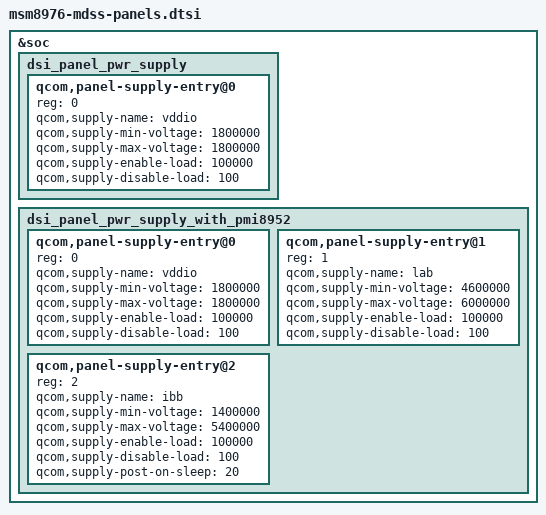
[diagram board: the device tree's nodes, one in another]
/* Copyright (c) 2015, The Linux Foundation. All rights reserved.
 *
 * This program is free software; you can redistribute it and/or modify
 * it under the terms of the GNU General Public License version 2 and
 * only version 2 as published by the Free Software Foundation.
 *
 * This program is distributed in the hope that it will be useful,
 * but WITHOUT ANY WARRANTY; without even the implied warranty of
 * MERCHANTABILITY or FITNESS FOR A PARTICULAR PURPOSE.  See the
 * GNU General Public License for more details.
 */

#include "dsi-panel-sim-video.dtsi"
#include "dsi-panel-sim-cmd.dtsi"
#include "dsi-panel-nt35597-dualmipi-wqxga-video.dtsi"
#include "dsi-panel-nt35597-dualmipi-wqxga-cmd.dtsi"
#include "dsi-panel-otm1906c-1080p-cmd.dtsi"
#include "dsi-panel-hx8399a-1080p-video.dtsi"
#include "dsi-panel-nt35597-dsc-wqxga-video.dtsi"
#include "dsi-panel-nt35597-dsc-wqxga-cmd.dtsi"
#include "dsi-panel-truly-1080p-video.dtsi"
#include "dsi-panel-truly-1080p-cmd.dtsi"
#include "dsi-panel-adv7533-1080p-video.dtsi"
#include "dsi-panel-adv7533-720p-video.dtsi"

/* [PLATFORM]-Mod-BEGIN by TCTNB.CY, FR-717274, 2015/10/19, add driver of FHD & WQHD*/
#include "dsi-panel-s6e3ha3-amoled-dualmipi-wqhd-cmd.dtsi"
#include "dsi-panel-s6e3fa3-amoled-fhd-cmd.dtsi"
/* [PLATFORM]-Mod-END by TCTNB.CY,  2015/10/19*/

#include "dsi-panel-nt35523-dualmipi-wqxga-video.dtsi"
&soc {
	dsi_panel_pwr_supply: dsi_panel_pwr_supply {
		#address-cells = <1>;
		#size-cells = <0>;
/* [PLATFORM]-Mod-BEGIN by TCTNB.CY, FR-526579, 2015/9/10, remove unused ldo power for amoled*/
/*
		qcom,panel-supply-entry@0 {
			reg = <0>;
			qcom,supply-name = "vdd";
			qcom,supply-min-voltage = <2850000>;
			qcom,supply-max-voltage = <2850000>;
			qcom,supply-enable-load = <100000>;
			qcom,supply-disable-load = <100>;
		};
*/
		qcom,panel-supply-entry@0 {
			reg = <0>;
			qcom,supply-name = "vddio";
			qcom,supply-min-voltage = <1800000>;
			qcom,supply-max-voltage = <1800000>;
			qcom,supply-enable-load = <100000>;
			qcom,supply-disable-load = <100>;
		};
/*
		qcom,panel-supply-entry@2 {
			reg = <2>;
			qcom,supply-name = "lab";
			qcom,supply-min-voltage = <4600000>;
			qcom,supply-max-voltage = <6000000>;
			qcom,supply-enable-load = <100000>;
			qcom,supply-disable-load = <100>;
		};

		qcom,panel-supply-entry@3 {
			reg = <3>;
			qcom,supply-name = "ibb";
			qcom,supply-min-voltage = <4600000>;
			qcom,supply-max-voltage = <6000000>;
			qcom,supply-enable-load = <100000>;
			qcom,supply-disable-load = <100>;
			qcom,supply-post-on-sleep = <20>;
		};
*/
/* [PLATFORM]-Mod-END by TCTNB.CY, 2015/9/10*/
	};

/* [PLATFORM]-Mod-BEGIN by TCTNB.CY, FR-764135, 2015/10/20, add pmi8952 amoled power supply*/
	dsi_panel_pwr_supply_with_pmi8952: dsi_panel_pwr_supply_with_pmi8952 {
		#address-cells = <1>;
		#size-cells = <0>;

		qcom,panel-supply-entry@0 {
			reg = <0>;
			qcom,supply-name = "vddio";
			qcom,supply-min-voltage = <1800000>;
			qcom,supply-max-voltage = <1800000>;
			qcom,supply-enable-load = <100000>;
			qcom,supply-disable-load = <100>;
		};

		qcom,panel-supply-entry@1 {
			reg = <1>;
			qcom,supply-name = "lab";
			qcom,supply-min-voltage = <4600000>;
			qcom,supply-max-voltage = <6000000>;
			qcom,supply-enable-load = <100000>;
			qcom,supply-disable-load = <100>;
		};

		qcom,panel-supply-entry@2 {
			reg = <2>;
			qcom,supply-name = "ibb";
			qcom,supply-min-voltage = <1400000>;
			qcom,supply-max-voltage = <5400000>;
			qcom,supply-enable-load = <100000>;
			qcom,supply-disable-load = <100>;
			qcom,supply-post-on-sleep = <20>;
		};
	};
/* [PLATFORM]-Mod-END by TCTNB.CY, 2015/10/20*/

};
